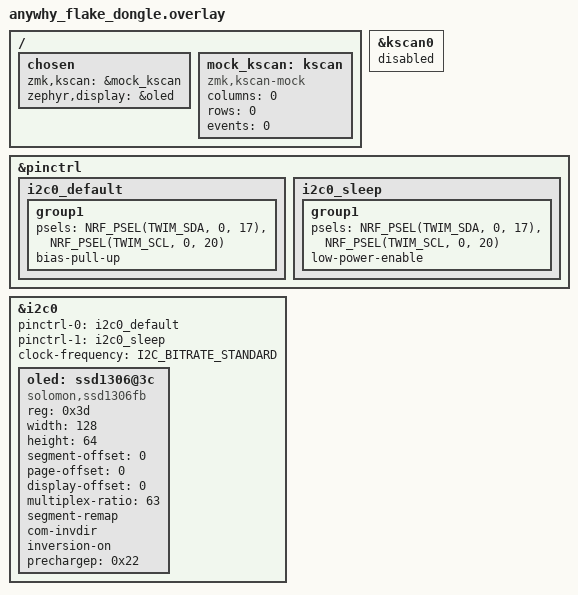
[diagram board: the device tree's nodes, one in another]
#include "anywhy_flake.dtsi"

/ {
    chosen {
        zmk,kscan = &mock_kscan;
        zephyr,display = &oled;
    };

    mock_kscan: kscan {
        compatible = "zmk,kscan-mock";
        columns = <0>;
        rows = <0>;
        events = <0>;
    };
};

/* Disable physical matrix inherited from base dtsi */
&kscan0 {
    status = "disabled";
};

/* 1. Define Pin Control for nice!nano Pro Micro I2C (017 = SDA, 020 = SCL) */
&pinctrl {
    i2c0_default: i2c0_default {
        group1 {
            psels = <NRF_PSEL(TWIM_SDA, 0, 17)>,
                    <NRF_PSEL(TWIM_SCL, 0, 20)>;
            bias-pull-up;
        };
    };

    i2c0_sleep: i2c0_sleep {
        group1 {
            psels = <NRF_PSEL(TWIM_SDA, 0, 17)>,
                    <NRF_PSEL(TWIM_SCL, 0, 20)>;
            low-power-enable;
        };
    };
};

/* 2. Assign pinctrl to i2c0 and initialize screen */
&i2c0 {
    status = "okay";
    pinctrl-0 = <&i2c0_default>;
    pinctrl-1 = <&i2c0_sleep>;
    pinctrl-names = "default", "sleep";
    clock-frequency = <I2C_BITRATE_STANDARD>; /* Force 100 kHz I2C clock */
    
    oled: ssd1306@3c {
        compatible = "solomon,ssd1306fb";
        reg = <0x3d>;
        width = <128>;
        height = <64>;
        segment-offset = <0>;
        page-offset = <0>;
        display-offset = <0>;
        multiplex-ratio = <63>;
        segment-remap;
        com-invdir;
        inversion-on;
        prechargep = <0x22>;
    };
};
